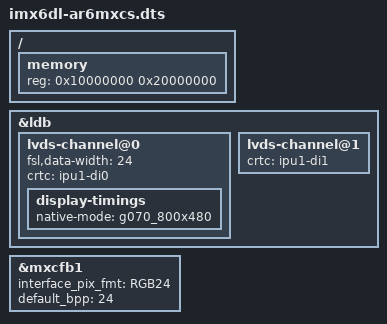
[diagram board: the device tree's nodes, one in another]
/*
 * Copyright (C) 2014 BCM Advanced Research
 *
 * This program is free software; you can redistribute it and/or modify
 * it under the terms of the GNU General Public License version 2 as
 * published by the Free Software Foundation.
 */

/dts-v1/;

#include "imx6dl.dtsi"
#include "imx6qdl-ar6mxcs.dtsi"
#include "imx6dl-ar6mxcs.dtsi"

/ {
	memory {
		reg = <0x10000000 0x20000000>;
	};
};

&ldb {
	lvds-channel@0 {
		fsl,data-width = <24>;
		crtc = "ipu1-di0";
		display-timings {
			native-mode = <&g070_800x480>;
		};
	};

	lvds-channel@1 {
		crtc = "ipu1-di1";
	};
};

&mxcfb1 {
	interface_pix_fmt = "RGB24";
	default_bpp = <24>;
};
